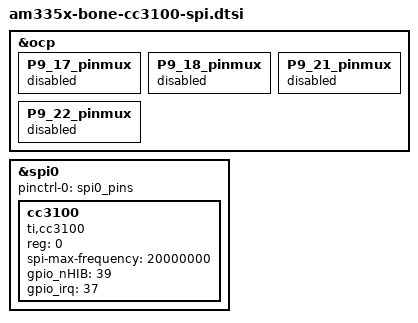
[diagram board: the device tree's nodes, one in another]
/*
 * Copyright (C) 2012 Texas Instruments Incorporated - http://www.ti.com/
 *
 * This program is free software; you can redistribute it and/or modify
 * it under the terms of the GNU General Public License version 2 as
 * published by the Free Software Foundation.
 */

/* include this file in am335x-bone.dts */

&ocp {
	P9_17_pinmux {
		status = "disabled";
	};
	P9_18_pinmux {
		status = "disabled";
	};
	P9_21_pinmux {
		status = "disabled";
	};
	P9_22_pinmux {
		status = "disabled";
	};
};

&spi0 {
	pinctrl-names = "default";
	pinctrl-0 = <&spi0_pins>;
	status = "okay";
	cc3100 {
		compatible = "ti,cc3100";
		reg = <0>;
		spi-max-frequency = <20000000>;
		gpio_nHIB = <39>; //P8_04
		gpio_irq= <37>;   //P8_22
	};
};
